# ATSAMG55J register map
Vendor: Microchip Technology; Series: SAMG55; File version: 0
CPU: CM4 r0p1, little endian, MPU, FPU, 4 interrupt priority bits
Registers are 32-bit, read-write, reset 0x0 unless marked. A register's access mark holds for its fields unless they carry their own. Offsets are from the block's base; [hi:lo] are bit positions; {n}, {i} and the like mark numbered series; 'fields as' and 'values as' point back to an identical list.

## SUPC — Supply Controller
Base 0x400E1410; register names take the prefix SUPC_
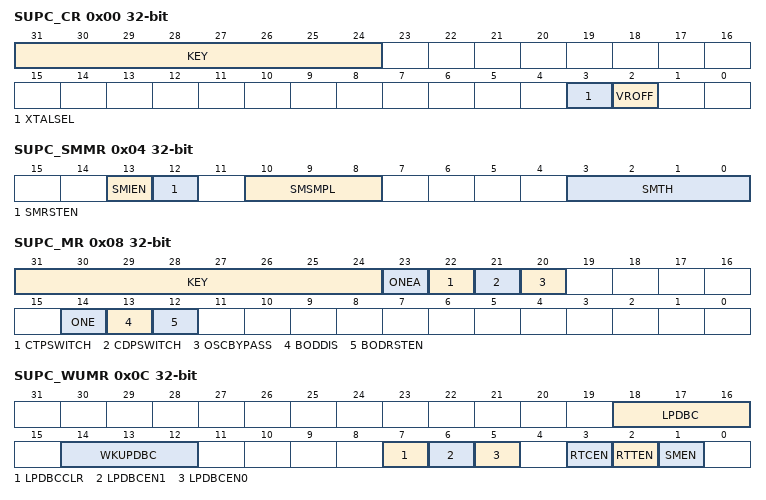
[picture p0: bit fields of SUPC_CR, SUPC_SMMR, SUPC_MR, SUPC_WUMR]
0x00 SUPC_CR wo — Supply Controller Control Register
  [31:24] KEY — Password
    165=PASSWD (Writing any other value in this field aborts the write operation.Always reads as 0.)
  [3] XTALSEL — Crystal Oscillator Select
    0=NO_EFFECT; 1=CRYSTAL_SEL (If KEY is correct, switches the slow clock on the crystal oscillator output.)
  [2] VROFF — Voltage Regulator Off
    0=NO_EFFECT; 1=STOP_VREG (If KEY is correct, asserts the system reset signal and stops the voltage regulator.)
0x04 SUPC_SMMR — Supply Controller Supply Monitor Mode Register
  [13] SMIEN — Supply Monitor Interrupt Enable
    0=NOT_ENABLE (The SUPC interrupt signal is not affected when a supply monitor detection occurs.); 1=ENABLE (The SUPC interrupt signal is asserted when a supply monitor detection occurs.)
  [12] SMRSTEN — Supply Monitor Reset Enable
    0=NOT_ENABLE (The core reset signal vddcore_nreset is not affected when a supply monitor detection occurs.); 1=ENABLE (The core reset signal vddcore_nreset is asserted when a supply monitor detection occurs.)
  [10:8] SMSMPL — Supply Monitor Sampling Period
    0=SMD (Supply Monitor disabled); 1=CSM (Continuous Supply Monitor); 2=_32SLCK (Supply Monitor enables one SLCK period every 32 SLCK periods); 3=_256SLCK (Supply Monitor enables one SLCK period every 256 SLCK periods); 4=_2048SLCK (Supply Monitor enables one SLCK period every 2,048 SLCK periods)
  [3:0] SMTH — Supply Monitor Threshold
    0=V1P6 (1.6 V); 1=V1P72 (1.72 V); 2=V1P84 (1.84 V); 3=V1P96 (1.96 V); 4=V2P08 (2.08 V); 5=V2P2 (2.2 V); 6=V2P32 (2.32 V); 7=V2P44 (2.44 V); 8=V2P56 (2.56 V); 9=V2P68 (2.68 V); 10=V2P8 (2.8 V); 11=V2P92 (2.92 V); 12=V3P04 (3.04 V); 13=V3P16 (3.16 V); 14=V3P28 (3.28 V); 15=V3P4 (3.4 V)
0x08 SUPC_MR — Supply Controller Mode Register
  [31:24] KEY — Password Key
    values as SUPC_CR.KEY
  [23] ONEA — This bit must always be set to 1.
  [22] CTPSWITCH — Cache Tag SRAM Power Switch
    0=OFF (The cache tag SRAM is not powered.); 1=ON (The cache tag SRAM is powered.)
  [21] CDPSWITCH — Cache Data SRAM Power Switch
    0=OFF (The cache data SRAM is not powered.); 1=ON (The cache data SRAM is powered.)
  [20] OSCBYPASS — Oscillator Bypass
    0=NO_EFFECT (No effect. Clock selection depends on XTALSEL value.); 1=BYPASS (The 32 kHz crystal oscillator is bypassed if XTALSEL=1. OSCBYPASS must be set prior to write XTALSEL=1.)
  [14] ONE — This bit must always be set to 1.
  [13] BODDIS — POR Core Disable
    0=ENABLE (The core brownout detector is enabled.); 1=DISABLE (The core brownout detector is disabled.)
  [12] BODRSTEN — POR Core Reset Enable
    0=NOT_ENABLE (The core reset signal vddcore_nreset is not affected when a brownout detection occurs.); 1=ENABLE (The core reset signal vddcore_nreset is asserted when a brownout detection occurs.)
0x0C SUPC_WUMR — Supply Controller Wake-up Mode Register
  [18:16] LPDBC — Low-power Debouncer Period
    0=DISABLE (Disable the low-power debouncers.); {v}=_{v+1}_RTCOUT0 (WKUP0/1 in active state for at least {v+1} RTCOUTx periods) (v=1..7)
  [14:12] WKUPDBC — Wake-up Inputs Debouncer Period
    0=IMMEDIATE (Immediate, no debouncing, detected active at least on one Slow Clock edge.); 1=_3_SCLK (WKUPx shall be in its active state for at least 3 SLCK periods); 2=_32_SCLK (WKUPx shall be in its active state for at least 32 SLCK periods); 3=_512_SCLK (WKUPx shall be in its active state for at least 512 SLCK periods); 4=_4096_SCLK (WKUPx shall be in its active state for at least 4,096 SLCK periods); 5=_32768_SCLK (WKUPx shall be in its active state for at least 32,768 SLCK periods)
  [7] LPDBCCLR — Low-power Debouncer Clear
    0=NOT_ENABLE (A low-power debounce event does not create an immediate clear on the first half of GPBR registers.); 1=ENABLE (A low-power debounce event on WKUP0 or WKUP1 generates an immediate clear on the first half of GPBR registers.)
  [6] LPDBCEN1 — Low-power Debouncer Enable WKUP1
    0=NOT_ENABLE (The WKUP1 input pin is not connected to the low-power debouncer.); 1=ENABLE (The WKUP1 input pin is connected to the low-power debouncer and forces a system wake-up.)
  [5] LPDBCEN0 — Low-power Debouncer Enable WKUP0
    0=NOT_ENABLE (The WKUP0 input pin is not connected to the low-power debouncer.); 1=ENABLE (The WKUP0 input pin is connected to the low-power debouncer and forces a system wake-up.)
  [3] RTCEN — Real-time Clock Wake-up Enable
    1=ENABLE (The RTC alarm signal forces the wake-up of the core power supply.)
  [2] RTTEN — Real-time Timer Wake-up Enable
    1=ENABLE (The RTT alarm signal forces the wake-up of the core power supply.)
  [1] SMEN — Supply Monitor Wake-up Enable
    0=NOT_ENABLE (The supply monitor detection has no wake-up effect.); 1=ENABLE (The supply monitor detection forces the wake-up of the core power supply.)
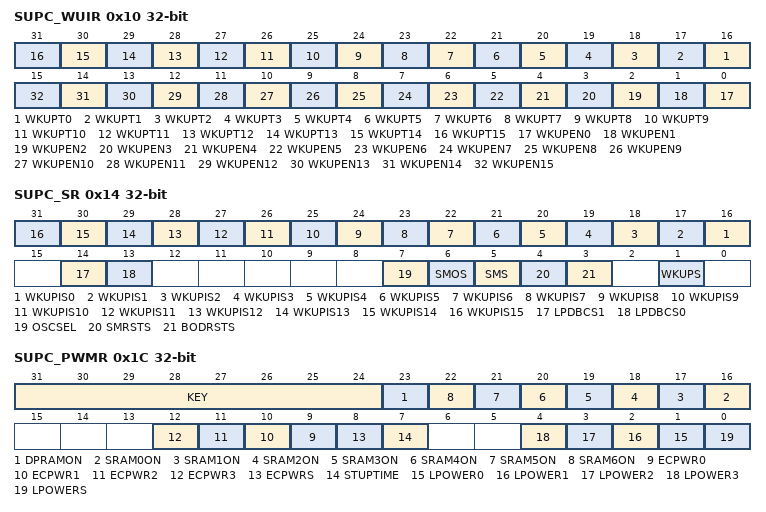
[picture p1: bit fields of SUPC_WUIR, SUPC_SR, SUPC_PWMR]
0x10 SUPC_WUIR — Supply Controller Wake-up Inputs Register
  [n+16] WKUPT{n} (n=0..15) — Wake-up Input Type {n}
    0=LOW (A falling edge followed by a low level for a period defined by WKUPDBC on the corresponding wake-up input forces the wake-up of the core power supply.); 1=HIGH (A rising edge followed by a high level for a period defined by WKUPDBC on the corresponding wake-up input forces the wake-up of the core power supply.)
  [n] WKUPEN{n} (n=0..15) — Wake-up Input Enable {n}
    0=DISABLE (The corresponding wake-up input has no wake-up effect.); 1=ENABLE (The corresponding wake-up input forces the wake-up of the core power supply.)
0x14 SUPC_SR ro — Supply Controller Status Register
  [n+16] WKUPIS{n} (n=0..15) — WKUP Input Status {n} (cleared on read)
    0=DISABLED (The corresponding wake-up input is disabled, or was inactive at the time the debouncer triggered a wake-up event.); 1=ENABLED (The corresponding wake-up input was active at the time the debouncer triggered a wake-up event since the last read of SUPC_SR.)
  [14] LPDBCS1 — Low-power Debouncer Wake-up Status on WKUP1 (cleared on read)
    0=NO (No wake-up due to the assertion of the WKUP1 pin has occurred since the last read of SUPC_SR.); 1=PRESENT (At least one wake-up due to the assertion of the WKUP1 pin has occurred since the last read of SUPC_SR.)
  [13] LPDBCS0 — Low-power Debouncer Wake-up Status on WKUP0 (cleared on read)
    0=NO (No wake-up due to the assertion of the WKUP0 pin has occurred since the last read of SUPC_SR.); 1=PRESENT (At least one wake-up due to the assertion of the WKUP0 pin has occurred since the last read of SUPC_SR.)
  [7] OSCSEL — 32-kHz Oscillator Selection Status
    0=RC (The slow clock SLCK is generated by the embedded 32 kHz RC oscillator.); 1=CRYST (The slow clock SLCK is generated by the 32 kHz crystal oscillator.)
  [6] SMOS — Supply Monitor Output Status
    0=HIGH (The supply monitor detected VDDIO higher than its threshold at its last measurement.); 1=LOW (The supply monitor detected VDDIO lower than its threshold at its last measurement.)
  [5] SMS — Supply Monitor Status (cleared on read)
    0=NO (No supply monitor detection since the last read of SUPC_SR.); 1=PRESENT (At least one supply monitor detection since the last read of SUPC_SR.)
  [4] SMRSTS — Supply Monitor Reset Status (cleared on read)
    0=NO (No supply monitor detection has generated a core reset since the last read of SUPC_SR.); 1=PRESENT (At least one supply monitor detection has generated a core reset since the last read of SUPC_SR.)
  [3] BODRSTS — Brownout Detector Reset Status (cleared on read)
    0=NO (No core brownout rising edge event has been detected since the last read of SUPC_SR.); 1=PRESENT (At least one brownout output rising edge event has been detected since the last read of SUPC_SR.)
  [1] WKUPS — WKUP Wake-up Status (cleared on read)
    0=NO (No wake-up due to the assertion of the WKUP pins has occurred since the last read of SUPC_SR.); 1=PRESENT (At least one wake-up due to the assertion of the WKUP pins has occurred since the last read of SUPC_SR.)
0x1C SUPC_PWMR — Supply Controller Power Mode Register
  [31:24] KEY — Password Key
    90=PASSWD (Writing any other value in this field aborts the write operation.Always reads as 0.)
  [23] DPRAMON — Dual-port RAM Power Control
    0=OFF (USB dual-port RAM is not powered.); 1=ON (USB dual-port RAM is powered.)
  [n+16] SRAM{n}ON (n=0..6) — SRAM Power Control
    0=OFF (SRAMx is not powered.); 1=ON (SRAMx is powered.)
  [n+9] ECPWR{n} (n=0..3) — Enhanced Custom Power Value
  [8] ECPWRS — Enhanced Custom Power Value Selection
    0=FACTORY (The trimming value applied to the regulator when the device is in Active mode. This value is factory-defined.); 1=USER (The trimming value applied to the regulator is defined by the value programmed in ECPWRx bits.)
  [7] STUPTIME — Start-up Time when Resuming from Wait Mode
    0=FAST (Fast start-up.); 1=SLOW (Slow start-up.)
  [n+1] LPOWER{n} (n=0..3) — Low Power Value
  [0] LPOWERS — Low Power Value Selection
    0=FACTORY (The trimming value applied to the regulator when the device is in Wait mode. This value is factory-defined.); 1=USER (The trimming value applied to the regulator is defined by the value programmed in the LPOWERx bits.)
